# APM32F107xx register map
File version: 1.0
CPU: CM3 r2p1, little endian, no MPU, no FPU, 4 interrupt priority bits
Registers are 32-bit, read-write, reset 0x0 unless marked. A register's access mark holds for its fields unless they carry their own. Offsets are from the block's base; [hi:lo] are bit positions; {n}, {i} and the like mark numbered series; 'fields as' and 'values as' point back to an identical list.

## OTG_FS_HOST — USB on the go full speed
Base 0x50000400
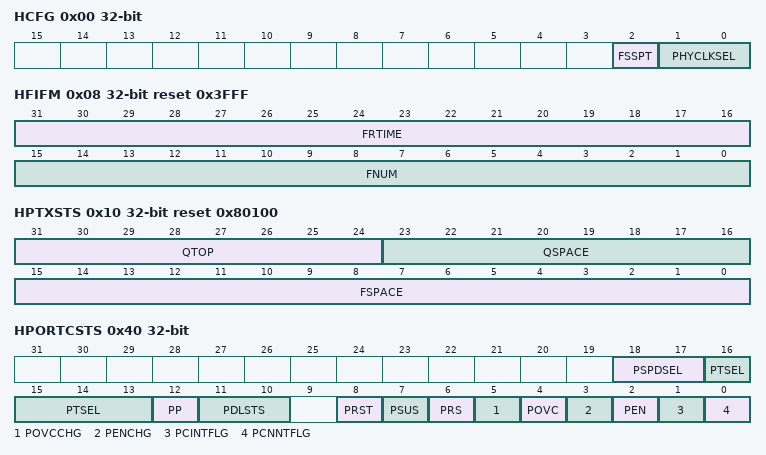
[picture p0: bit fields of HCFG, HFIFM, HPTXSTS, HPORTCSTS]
0x00 HCFG access per field — OTG_FS host configuration register (OTG_FS_HCFG)
  [2] FSSPT ro — FS- and LS-only support
  [1:0] PHYCLKSEL rw — FS/LS PHY clock select
0x04 HFIVL reset 0xEA60 — OTG_FS Host frame interval register
  [15:0] FIVL — Frame interval
0x08 HFIFM ro reset 0x3FFF — OTG_FS host frame number/frame time remaining register (OTG_FS_HFNUM)
  [31:16] FRTIME — Frame time remaining
  [15:0] FNUM — Frame number
0x10 HPTXSTS access per field reset 0x80100 — OTG_FS_Host periodic transmit FIFO/queue status register (OTG_FS_HPTXSTS)
  [31:24] QTOP ro — Top of the periodic transmit request queue
  [23:16] QSPACE ro — Periodic transmit request queue space available
  [15:0] FSPACE rw — Periodic transmit data FIFO space available
0x14 HACHINT ro — OTG_FS Host all channels interrupt register
  [15:0] ACHINT — Channel interrupts
0x18 HACHIMASK — OTG_FS host all channels interrupt mask register
  [15:0] ACHIMASK — Channel interrupt mask
0x40 HPORTCSTS access per field — OTG_FS host port control and status register (OTG_FS_HPRT)
  [18:17] PSPDSEL ro — Port speed
  [16:13] PTSEL rw — Port test control
  [12] PP rw — Port power
  [11:10] PDLSTS ro — Port line status
  [8] PRST rw — Port reset
  [7] PSUS rw — Port suspend
  [6] PRS rw — Port resume
  [5] POVCCHG rw — Port overcurrent change
  [4] POVC ro — Port overcurrent active
  [3] PENCHG rw — Port enable/disable change
  [2] PEN rw — Port enable
  [1] PCINTFLG rw — Port connect detected
  [0] PCNNTFLG ro — Port connect status
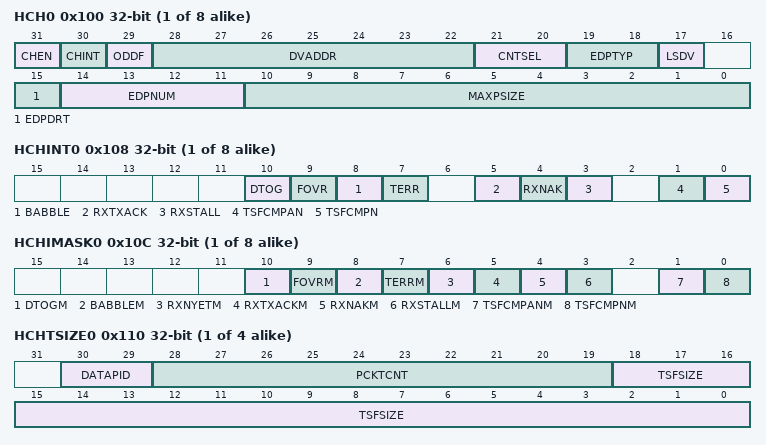
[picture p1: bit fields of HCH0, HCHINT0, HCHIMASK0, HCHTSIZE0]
{0x100+0x20*i} HCH{i} (i=0..7) — OTG_FS host channel-{i} characteristics register (OTG_FS_HCCHAR{i})
  [31] CHEN — Channel enable
  [30] CHINT — Channel disable
  [29] ODDF — Odd frame
  [28:22] DVADDR — Device address
  [21:20] CNTSEL — Multicount
  [19:18] EDPTYP — Endpoint type
  [17] LSDV — Low-speed device
  [15] EDPDRT — Endpoint direction
  [14:11] EDPNUM — Endpoint number
  [10:0] MAXPSIZE — Maximum packet size
{0x108+0x20*i} HCHINT{i} (i=0..7) — OTG_FS host channel-{i} interrupt register (OTG_FS_HCINT{i})
  [10] DTOG — Data toggle error
  [9] FOVR — Frame overrun
  [8] BABBLE — Babble error
  [7] TERR — Transaction error
  [5] RXTXACK — ACK response received/transmitted interrupt
  [4] RXNAK — NAK response received interrupt
  [3] RXSTALL — STALL response received interrupt
  [1] TSFCMPAN — Channel halted
  [0] TSFCMPN — Transfer completed
{0x10C+0x20*i} HCHIMASK{i} (i=0..7) — OTG_FS host channel-{i} mask register (OTG_FS_HCINTMSK{i})
  [10] DTOGM — Data toggle error mask
  [9] FOVRM — Frame overrun mask
  [8] BABBLEM — Babble error mask
  [7] TERRM — Transaction error mask
  [6] RXNYETM — response received interrupt mask
  [5] RXTXACKM — ACK response received/transmitted interrupt mask
  [4] RXNAKM — NAK response received interrupt mask
  [3] RXSTALLM — STALL response received interrupt mask
  [1] TSFCMPANM — Channel halted mask
  [0] TSFCMPNM — Transfer completed mask
{0x110+0x20*i} HCHTSIZE{i} (i=0..3) — OTG_FS host channel-{i} transfer size register
  [30:29] DATAPID
  [28:19] PCKTCNT — Packet count
  [18:0] TSFSIZE — Transfer size
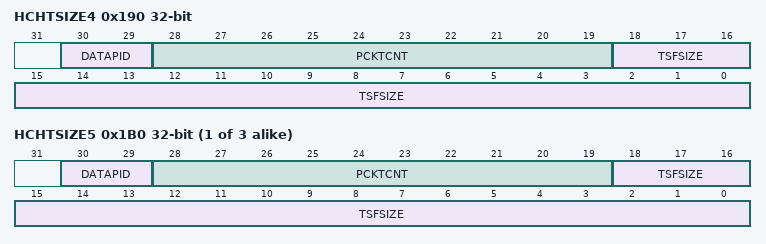
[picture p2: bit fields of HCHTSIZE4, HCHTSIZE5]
0x190 HCHTSIZE4 — OTG_FS host channel-x transfer size register
  fields as HCHTSIZE0
{0x110+0x20*i} HCHTSIZE{i} (i=5..7) — OTG_FS host channel-{i} transfer size register
  fields as HCHTSIZE0

## OTG_FS_PWRCLK — USB on the go full speed
Base 0x50000E00
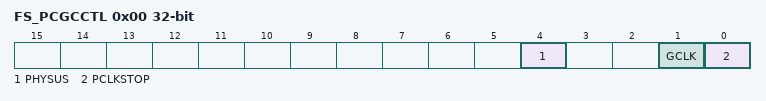
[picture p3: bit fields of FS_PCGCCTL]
0x00 FS_PCGCCTL — OTG_FS power and clock gating control register
  [4] PHYSUS — PHY Suspended
  [1] GCLK — Gate HCLK
  [0] PCLKSTOP — Stop PHY clock

## Ethernet_MAC — Ethernet: media access control
Base 0x40028000
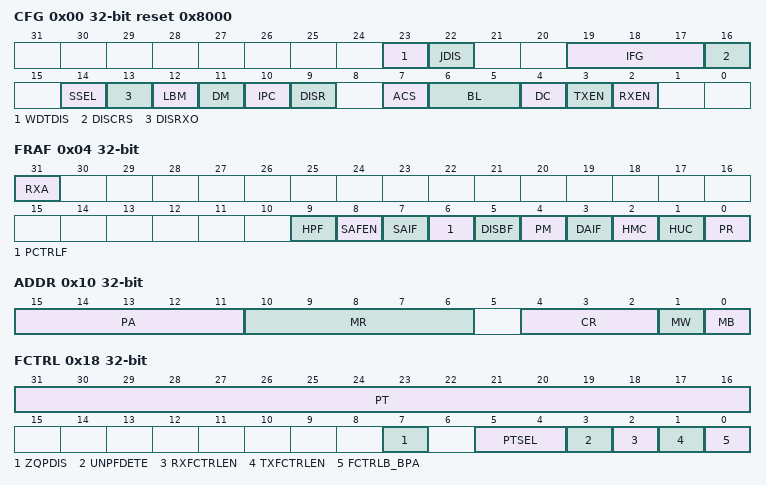
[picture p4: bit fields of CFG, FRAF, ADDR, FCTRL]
0x00 CFG reset 0x8000 — Ethernet MAC configuration register
  [23] WDTDIS — Watchdog Disable
  [22] JDIS — Jabber Disable
  [19:17] IFG — Inter-Frame Gap
  [16] DISCRS — Disable Carrier Sense During Transmission
  [14] SSEL — Speed
  [13] DISRXO — Disable Receive Own
  [12] LBM — Loopback Mode
  [11] DM — Duplex Mode
  [10] IPC — IPv4 Checksum offload
  [9] DISR — Disable Retry
  [7] ACS — Automatic Pad or CRC Stripping
  [6:5] BL — Back off Limit
  [4] DC — Deferral Check
  [3] TXEN — Transmitter Enable
  [2] RXEN — Receiver Enable
0x04 FRAF — Ethernet MAC frame filter register
  [31] RXA — Receive All
  [9] HPF — Hash or Perfect Filter
  [8] SAFEN — Source Address Filter Enable
  [7] SAIF — SA Inverse Filtering
  [6] PCTRLF — Pass Control Frames
  [5] DISBF — Disable Broadcast Frames
  [4] PM — Pass All Multicast
  [3] DAIF — DA Inverse Filtering
  [2] HMC — Hash Multicast
  [1] HUC — Hash Unicast
  [0] PR — Promiscuous Mode
0x08 HTH — Ethernet MAC hash table high register
  [31:0] HTH — Hash Table High
0x0C HTL — Ethernet MAC hash table low register
  [31:0] HTL — Hash Table Low
0x10 ADDR — Ethernet MAC MII address register
  [15:11] PA — Physical Layer Address
  [10:6] MR — MII Register
  [4:2] CR — Clock Range
  [1] MW — MII Write
  [0] MB — MII Busy
0x14 DATA — Ethernet MAC MII data register
  [15:0] MD — MII Data
0x18 FCTRL — Ethernet MAC flow control register
  [31:16] PT — Pause Time
  [7] ZQPDIS — Zero-quanta Pause Disable
  [5:4] PTSEL — Pause Threshold Select
  [3] UNPFDETE — Unicast Pause Frame Detect
  [2] RXFCTRLEN — Receive Flow Control Enable
  [1] TXFCTRLEN — Transmit Flow Control Enable
  [0] FCTRLB_BPA — Flow Control Busy/Back Pressure Activate
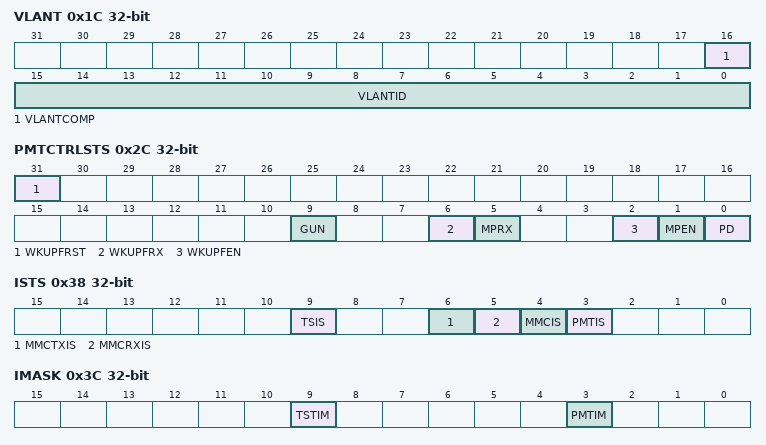
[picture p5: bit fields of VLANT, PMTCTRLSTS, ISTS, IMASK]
0x1C VLANT — Ethernet MAC VLAN tag register
  [16] VLANTCOMP — 12-bit VLAN Tag Comparison
  [15:0] VLANTID — VLAN Tag Identifier
0x28 REMWKUPFFL — Ethernet MAC PMT control and status register
0x2C PMTCTRLSTS ro — Ethernet MAC debug register
  [31] WKUPFRST — Wakeup Frame Filter Register Pointer Reset
  [9] GUN — Global Unicast
  [6] WKUPFRX — Wakeup Frame Received
  [5] MPRX — Magic Packet Received
  [2] WKUPFEN — Wakeup Frame Enable
  [1] MPEN — Magic Packet Enable
  [0] PD — Power Down
0x38 ISTS access per field — Ethernet MAC interrupt status register
  [9] TSIS rw — Timestamp Interrupt Status
  [6] MMCTXIS ro — MMC Transmit Interrupt Status
  [5] MMCRXIS ro — MMC Receive Interrupt Status
  [4] MMCIS ro — MMC Interrupt Status
  [3] PMTIS ro — PMT Interrupt Status
0x3C IMASK — Ethernet MAC interrupt mask register
  [9] TSTIM — Time Stamp Trigger Interrupt Mask
  [3] PMTIM — PMT Interrupt Mask
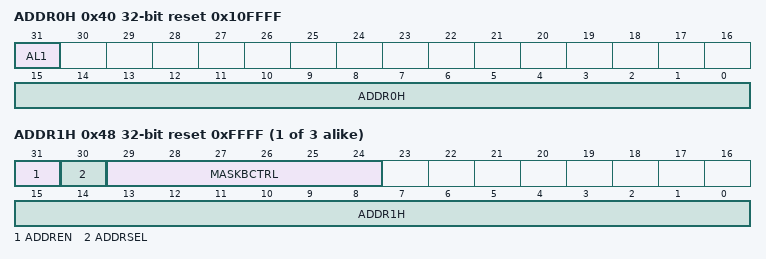
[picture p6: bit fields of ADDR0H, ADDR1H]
0x40 ADDR0H access per field reset 0x10FFFF — Ethernet MAC address 0 high register
  [31] AL1 ro — Always 1
  [15:0] ADDR0H rw — MAC address0 high
0x44 ADDR0L reset 0xFFFFFFFF — Ethernet MAC address 0 low register
  [31:0] ADDR0L — MAC Address 0
{0x40+8i} ADDR{i}H reset 0xFFFF (i=1..3) — Ethernet MAC address {i} high register
  [31] ADDREN — Address Enable
  [30] ADDRSEL — Address Select
  [29:24] MASKBCTRL — Mask Byte Control
  [15:0] ADDR{i}H — MAC Address {i}
0x4C ADDR1L reset 0xFFFFFFFF — Ethernet MAC address1 low register
  [31:0] ADDR1L — MAC Address 1
0x54 ADDR2L reset 0xFFFFFFFF — Ethernet MAC address 2 low register
  [30:0] ADDR2L — MAC Address 2
0x5C ADDR3L reset 0xFFFFFFFF — Ethernet MAC address 3 low register
  [31:0] ADDR3L — MAC Address 3

## Ethernet_MMC — Ethernet: MAC management counters
Base 0x40028100
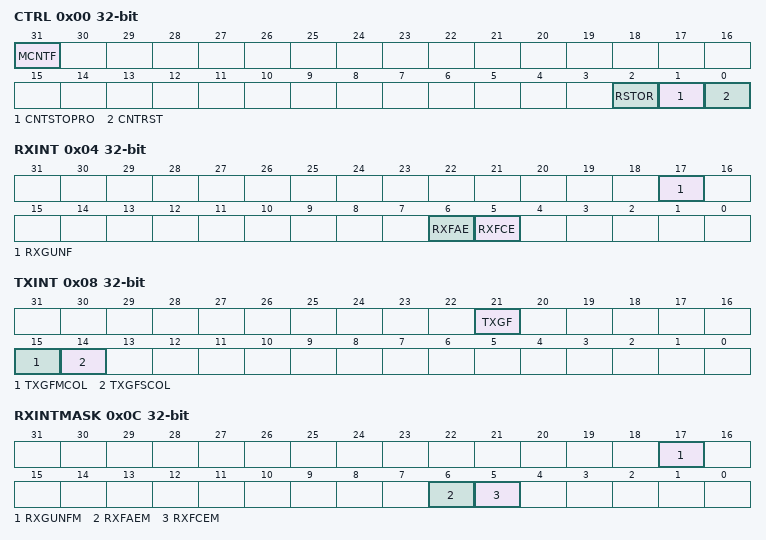
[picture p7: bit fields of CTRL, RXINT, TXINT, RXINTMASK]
0x00 CTRL — Ethernet MMC control register
  [31] MCNTF — MMC counter freeze
  [2] RSTOR — Reset on read
  [1] CNTSTOPRO — Counter stop rollover
  [0] CNTRST — Counter reset
0x04 RXINT — Ethernet MMC receive interrupt register
  [17] RXGUNF — Received Good Unicast Frames Status
  [6] RXFAE — Received frames alignment error status
  [5] RXFCE — Received frames CRC error status
0x08 TXINT — Ethernet MMC transmit interrupt register
  [21] TXGF — Transmitted good frames status
  [15] TXGFMCOL — Transmitted good frames more single collision status
  [14] TXGFSCOL — Transmitted good frames single collision status
0x0C RXINTMASK — Ethernet MMC receive interrupt mask register
  [17] RXGUNFM — Received good unicast frames mask
  [6] RXFAEM — Received frames alignment error mask
  [5] RXFCEM — Received frame CRC error mask
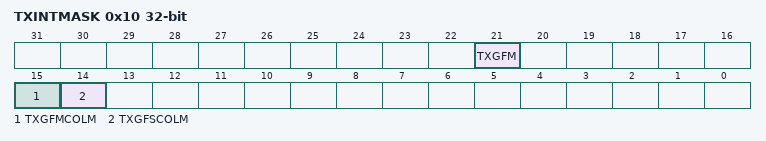
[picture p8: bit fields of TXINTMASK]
0x10 TXINTMASK — Ethernet MMC transmit interrupt mask register
  [21] TXGFM — Transmitted good frames mask
  [15] TXGFMCOLM — Transmitted good frames more single collision mask
  [14] TXGFSCOLM — Transmitted good frames single collision mask
0x4C TXGFSCCNT ro — Ethernet MMC transmitted good frames after a single collision counter
  [31:0] TXGFSCCNT — Transmitted good frames after a single collision counter
0x50 TXGFMCCNT ro — Ethernet MMC transmitted good frames after more than a single collision
  [31:0] TXGFMCCNT — Transmitted good frames after more than a single collision counter
0x68 TXGFCNT ro — Ethernet MMC transmitted good frames counter register
  [31:0] TXGFCNT — Transmitted good frames counter
0x94 RXFCECNT ro — Ethernet MMC received frames with CRC error counter register
  [31:0] RXFCECNT — Received frames with CRC error counter
0x98 RXFAECNT ro — Ethernet MMC received frames with alignment error counter register
  [31:0] RXFAECNT — Received frames with alignment error counter
0xC4 RXGUNCNT ro — MMC received good unicast frames counter register
  [31:0] RXGUNCNT — Received good unicast frames counter

## Ethernet_PTP — Ethernet: Precision time protocol
Base 0x40028700
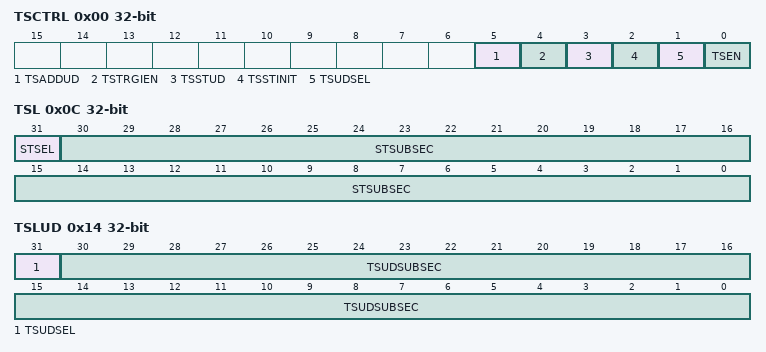
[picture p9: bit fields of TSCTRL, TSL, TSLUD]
0x00 TSCTRL — Ethernet PTP time stamp control register
  [5] TSADDUD — Time stamp addend register update
  [4] TSTRGIEN — Time stamp interrupt trigger enable
  [3] TSSTUD — Time stamp system time update
  [2] TSSTINIT — Time stamp system time initialize
  [1] TSUDSEL — Time stamp fine or coarse update
  [0] TSEN — Time stamp enable
0x04 SUBSECI — Ethernet PTP subsecond increment register
  [7:0] STSUBSECI — System time subsecond increment
0x08 TSH ro — Ethernet PTP time stamp high register
  [31:0] STSEC — System time second
0x0C TSL ro — Ethernet PTP time stamp low register
  [31] STSEL — System time positive or negative sign
  [30:0] STSUBSEC — System time subseconds
0x10 TSHUD — Ethernet PTP time stamp high update register
  [31:0] TSUDSEC — Time stamp update second
0x14 TSLUD — Ethernet PTP time stamp low update register
  [31] TSUDSEL — Time stamp update positive or negative sign
  [30:0] TSUDSUBSEC — Time stamp update subseconds
0x18 TSA — Ethernet PTP time stamp addend register
  [31:0] TSA — Time stamp addend
0x1C TTSH — Ethernet PTP target time high register
  [31:0] TTSH — Target time stamp high
0x20 TTSL — Ethernet PTP target time low register
  [31:0] TTSL — Target time stamp low
